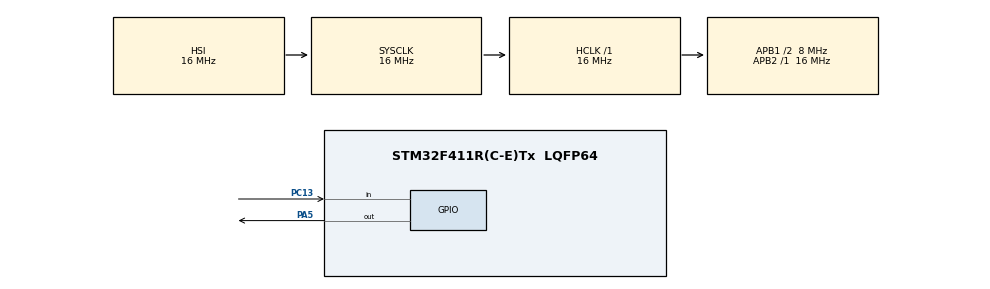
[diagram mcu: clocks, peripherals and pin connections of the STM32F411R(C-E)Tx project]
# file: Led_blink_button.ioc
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Mcu.Family=STM32F4
RCC.CortexFreq_Value=16000000
RCC.APB1CLKDivider=RCC_HCLK_DIV2
ProjectManager.StackSize=0x400
PA13.Signal=SYS_JTMS-SWDIO
ProjectManager.TargetToolchain=MDK-ARM V5.27
RCC.HCLKFreq_Value=16000000
RCC.APB2TimFreq_Value=16000000
RCC.AHBFreq_Value=16000000
PA5.Signal=GPIO_Output
RCC.HSE_VALUE=8000000
board=NUCLEO-F411RE
PC13-ANTI_TAMP.Signal=GPIO_Input
RCC.VCOOutputFreq_Value=336000000
RCC.APB2Freq_Value=16000000
PA14.Mode=Serial_Wire
PA13.Mode=Serial_Wire
Mcu.Name=STM32F411R(C-E)Tx
RCC.FLatency-AdvancedSettings=FLASH_LATENCY_0
RCC.48MHZClocksFreq_Value=84000000
RCC.SYSCLKFreq_VALUE=16000000
Mcu.Package=LQFP64
PA14.Signal=SYS_JTCK-SWCLK
ProjectManager.HeapSize=0x200
RCC.HSI_VALUE=16000000
RCC.PLLP=RCC_PLLP_DIV4
NVIC.PriorityGroup=NVIC_PRIORITYGROUP_0
RCC.PLLN=336
RCC.APB1TimFreq_Value=16000000
RCC.APB1Freq_Value=8000000

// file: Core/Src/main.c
/* USER CODE BEGIN Header */
/**
  ******************************************************************************
  * @file           : main.c
  * @brief          : Main program body
  ******************************************************************************
  * @attention
  *
  * <h2><center>&copy; Copyright (c) 2020 STMicroelectronics.
  * All rights reserved.</center></h2>
  *
  * This software component is licensed by ST under BSD 3-Clause license,
  * the "License"; You may not use this file except in compliance with the
  * License. You may obtain a copy of the License at:
  *                        opensource.org/licenses/BSD-3-Clause
  *
  ******************************************************************************
  */
/* USER CODE END Header */
#include "main.h"

/* USER CODE BEGIN Includes */
#include "stdbool.h"

/* USER CODE END Includes */

void SystemClock_Config(void);
static void MX_GPIO_Init(void);
/* USER CODE BEGIN PFP */
bool notPressed= true;

/* USER CODE END PFP */

int main(void)
{

  /* MCU Configuration--------------------------------------------------------*/

  /* Reset of all peripherals, Initializes the Flash interface and the Systick. */
  HAL_Init();

  /* Configure the system clock */
  SystemClock_Config();

  /* Initialize all configured peripherals */
  MX_GPIO_Init();

  /* Infinite loop */
  while (1)
  {

    /* USER CODE BEGIN 3 */
		if(HAL_GPIO_ReadPin(GPIOC,GPIO_PIN_13) && notPressed){
			HAL_GPIO_TogglePin(GPIOA,GPIO_PIN_5);
			notPressed=false;

		}
		else if(HAL_GPIO_ReadPin(GPIOC,GPIO_PIN_13)==GPIO_PIN_RESET)
			notPressed=true;

		/*if(HAL_GPIO_ReadPin(GPIOC,GPIO_PIN_13))

			HAL_GPIO_WritePin(GPIOA,GPIO_PIN_5,0);

		else
			HAL_GPIO_WritePin(GPIOA,GPIO_PIN_5,1);
			*/
  }
  /* USER CODE END 3 */
}

void SystemClock_Config(void)
{
  RCC_OscInitTypeDef RCC_OscInitStruct = {0};
  RCC_ClkInitTypeDef RCC_ClkInitStruct = {0};

  /** Configure the main internal regulator output voltage
  */
  __HAL_RCC_PWR_CLK_ENABLE();
  __HAL_PWR_VOLTAGESCALING_CONFIG(PWR_REGULATOR_VOLTAGE_SCALE1);
  /** Initializes the RCC Oscillators according to the specified parameters
  * in the RCC_OscInitTypeDef structure.
  */
  RCC_OscInitStruct.OscillatorType = RCC_OSCILLATORTYPE_HSI;
  RCC_OscInitStruct.HSIState = RCC_HSI_ON;
  RCC_OscInitStruct.HSICalibrationValue = RCC_HSICALIBRATION_DEFAULT;
  RCC_OscInitStruct.PLL.PLLState = RCC_PLL_NONE;
  if (HAL_RCC_OscConfig(&RCC_OscInitStruct) != HAL_OK)
  {
    Error_Handler();
  }
  /** Initializes the CPU, AHB and APB buses clocks
  */
  RCC_ClkInitStruct.ClockType = RCC_CLOCKTYPE_HCLK|RCC_CLOCKTYPE_SYSCLK
                              |RCC_CLOCKTYPE_PCLK1|RCC_CLOCKTYPE_PCLK2;
  RCC_ClkInitStruct.SYSCLKSource = RCC_SYSCLKSOURCE_HSI;
  RCC_ClkInitStruct.AHBCLKDivider = RCC_SYSCLK_DIV1;
  RCC_ClkInitStruct.APB1CLKDivider = RCC_HCLK_DIV2;
  RCC_ClkInitStruct.APB2CLKDivider = RCC_HCLK_DIV1;

  if (HAL_RCC_ClockConfig(&RCC_ClkInitStruct, FLASH_LATENCY_0) != HAL_OK)
  {
    Error_Handler();
  }
}

static void MX_GPIO_Init(void)
{
  GPIO_InitTypeDef GPIO_InitStruct = {0};

  /* GPIO Ports Clock Enable */
  __HAL_RCC_GPIOC_CLK_ENABLE();
  __HAL_RCC_GPIOA_CLK_ENABLE();

  /*Configure GPIO pin Output Level */
  HAL_GPIO_WritePin(GPIOA, GPIO_PIN_5, GPIO_PIN_RESET);

  /*Configure GPIO pin : PC13 */
  GPIO_InitStruct.Pin = GPIO_PIN_13;
  GPIO_InitStruct.Mode = GPIO_MODE_INPUT;
  GPIO_InitStruct.Pull = GPIO_NOPULL;
  HAL_GPIO_Init(GPIOC, &GPIO_InitStruct);

  /*Configure GPIO pin : PA5 */
  GPIO_InitStruct.Pin = GPIO_PIN_5;
  GPIO_InitStruct.Mode = GPIO_MODE_OUTPUT_PP;
  GPIO_InitStruct.Pull = GPIO_NOPULL;
  GPIO_InitStruct.Speed = GPIO_SPEED_FREQ_LOW;
  HAL_GPIO_Init(GPIOA, &GPIO_InitStruct);

}

void Error_Handler(void)
{
}

/************************ (C) COPYRIGHT STMicroelectronics *****END OF FILE****/
